VERSION ""

NS_ :

BS_:

BU_: Motor MotorController

BO_ 3221225472 VECTOR__INDEPENDENT_SIG_MSG: 0 Vector__XXX
 SG_ RFU : 32|8@1+ (1,0) [0|0] "" Vector__XXX

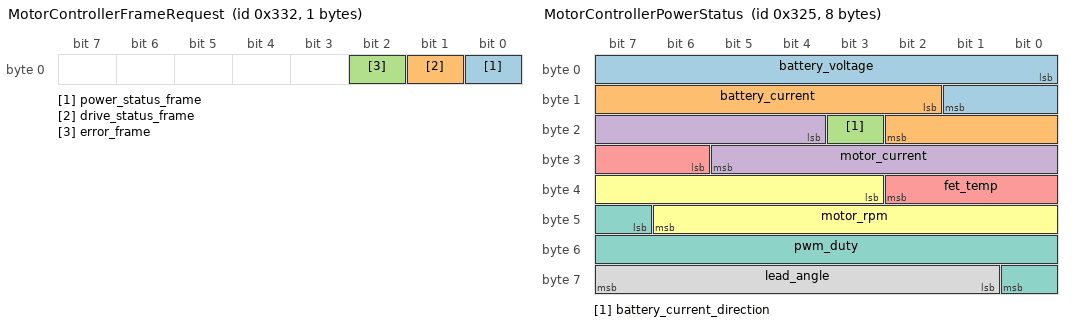
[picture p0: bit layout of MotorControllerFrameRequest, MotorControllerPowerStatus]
BO_ 818 MotorControllerFrameRequest: 1 Motor
 SG_ power_status_frame : 0|1@1+ (1,0) [0|0] "" Vector__XXX
 SG_ drive_status_frame : 1|1@1+ (1,0) [0|0] "" Vector__XXX
 SG_ error_frame : 2|1@1+ (1,0) [0|0] "" Vector__XXX

BO_ 805 MotorControllerPowerStatus: 8 MotorController
 SG_ battery_voltage : 0|10@1+ (0.5,0) [0|0] "V" Vector__XXX
 SG_ battery_current : 10|9@1+ (1,0) [0|0] "A" Vector__XXX
 SG_ battery_current_direction : 19|1@1+ (1,0) [0|0] "" Vector__XXX
 SG_ motor_current : 20|10@1+ (1,0) [0|0] "A" Vector__XXX
 SG_ fet_temp : 30|5@1+ (5,0) [0|0] "ºC" Vector__XXX
 SG_ motor_rpm : 35|12@1+ (1,0) [0|0] "RPM" Vector__XXX
 SG_ pwm_duty : 47|10@1+ (0.5,0) [0|0] "%" Vector__XXX
 SG_ lead_angle : 57|7@1+ (0.5,0) [0|0] "º" Vector__XXX

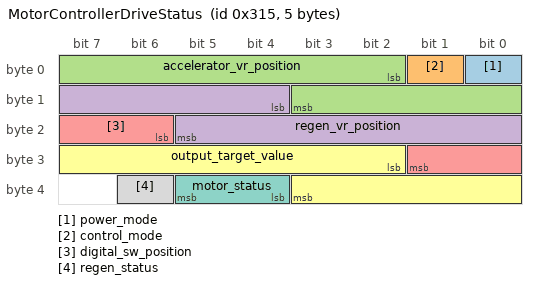
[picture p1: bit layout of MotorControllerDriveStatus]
BO_ 789 MotorControllerDriveStatus: 5 MotorController
 SG_ power_mode : 0|1@1+ (1,0) [0|0] "" Vector__XXX
 SG_ control_mode : 1|1@1+ (1,0) [0|0] "" Vector__XXX
 SG_ accelerator_vr_position : 2|10@1+ (0.5,0) [0|0] "" Vector__XXX
 SG_ regen_vr_position : 12|10@1+ (0.5,0) [0|0] "" Vector__XXX
 SG_ digital_sw_position : 22|4@1+ (1,0) [0|0] "" Vector__XXX
 SG_ output_target_value : 26|10@1+ (0.5,0) [0|0] "" Vector__XXX
 SG_ motor_status : 36|2@1+ (1,0) [0|0] "" Vector__XXX
 SG_ regen_status : 38|1@1+ (1,0) [0|0] "" Vector__XXX

BO_ 277 MotorControllerError: 5 MotorController
 SG_ analog_sensor_err : 0|1@1+ (1,0) [0|0] "" Vector__XXX
 SG_ motor_current_sensor_u_err : 1|1@1+ (1,0) [0|0] "" Vector__XXX
 SG_ motor_current_sensor_w_err : 2|1@1+ (1,0) [0|0] "" Vector__XXX
 SG_ fet_thermistor_err : 3|1@1+ (1,0) [0|0] "" Vector__XXX
 SG_ battery_voltage_sensor_err : 5|1@1+ (1,0) [0|0] "" Vector__XXX
 SG_ battery_current_sensor_err : 6|1@1+ (1,0) [0|0] "" Vector__XXX
 SG_ battery_current_sensor_adj_err : 7|1@1+ (1,0) [0|0] "" Vector__XXX
 SG_ motor_current_sensor_adj_err : 8|1@1+ (1,0) [0|0] "" Vector__XXX
 SG_ accelerator_position_err : 9|1@1+ (1,0) [0|0] "" Vector__XXX
 SG_ controller_voltage_sensor_err : 11|1@1+ (1,0) [0|0] "" Vector__XXX
 SG_ power_system_err : 16|1@1+ (1,0) [0|0] "" Vector__XXX
 SG_ overcurrent_err : 17|1@1+ (1,0) [0|0] "" Vector__XXX
 SG_ overvoltage_err : 19|1@1+ (1,0) [0|0] "" Vector__XXX
 SG_ overcurrent_limit : 21|1@1+ (1,0) [0|0] "" Vector__XXX
 SG_ motor_system_err : 24|1@1+ (1,0) [0|0] "" Vector__XXX
 SG_ motor_lock : 25|1@1+ (1,0) [0|0] "" Vector__XXX
 SG_ hall_sensor_short : 26|1@1+ (1,0) [0|0] "" Vector__XXX
 SG_ hall_sensor_open : 27|1@1+ (1,0) [0|0] "" Vector__XXX
 SG_ overheat_level : 32|2@1+ (1,0) [0|0] "" Vector__XXX

CM_ SG_ 277 analog_sensor_err "fault";
CM_ SG_ 277 motor_current_sensor_u_err "fault";
CM_ SG_ 277 motor_current_sensor_w_err "fault";
CM_ SG_ 277 fet_thermistor_err "fault";
CM_ SG_ 277 battery_voltage_sensor_err "fault";
CM_ SG_ 277 battery_current_sensor_err "fault";
CM_ SG_ 277 battery_current_sensor_adj_err "fault";
CM_ SG_ 277 motor_current_sensor_adj_err "fault";
CM_ SG_ 277 accelerator_position_err "fault";
CM_ SG_ 277 controller_voltage_sensor_err "fault";
CM_ SG_ 277 power_system_err "fault";
CM_ SG_ 277 overcurrent_err "fault";
CM_ SG_ 277 overvoltage_err "fault";
CM_ SG_ 277 overcurrent_limit "fault";
CM_ SG_ 277 motor_system_err "fault";
CM_ SG_ 277 motor_lock "fault";
CM_ SG_ 277 hall_sensor_short "fault";
CM_ SG_ 277 hall_sensor_open "fault";
CM_ SG_ 277 overheat_level "fault";
